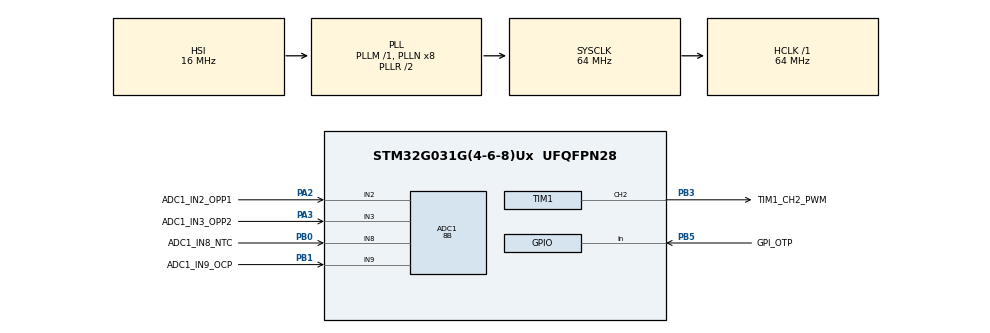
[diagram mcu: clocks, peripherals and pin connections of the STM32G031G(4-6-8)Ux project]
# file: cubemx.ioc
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ADC1.Channel-0\#ChannelRegularConversion=ADC_CHANNEL_2
ADC1.Channel-1\#ChannelRegularConversion=ADC_CHANNEL_3
ADC1.Channel-2\#ChannelRegularConversion=ADC_CHANNEL_8
ADC1.Channel-3\#ChannelRegularConversion=ADC_CHANNEL_9
ADC1.ClockPrescaler=ADC_CLOCK_ASYNC_DIV128
ADC1.ContinuousConvMode=ENABLE
ADC1.DMAContinuousRequests=ENABLE
ADC1.EOCSelection=ADC_EOC_SEQ_CONV
ADC1.ExternalTrigConv=ADC_SOFTWARE_START
ADC1.NbrOfConversion=4
ADC1.NbrOfConversionFlag=1
ADC1.Overrun=ADC_OVR_DATA_OVERWRITTEN
ADC1.Rank-0\#ChannelRegularConversion=1
ADC1.Rank-1\#ChannelRegularConversion=2
ADC1.Rank-2\#ChannelRegularConversion=3
ADC1.Rank-3\#ChannelRegularConversion=4
ADC1.Resolution=ADC_RESOLUTION_8B
ADC1.SamplingTime-0\#ChannelRegularConversion=ADC_SAMPLINGTIME_COMMON_1
ADC1.SamplingTime-1\#ChannelRegularConversion=ADC_SAMPLINGTIME_COMMON_1
ADC1.SamplingTime-2\#ChannelRegularConversion=ADC_SAMPLINGTIME_COMMON_1
ADC1.SamplingTime-3\#ChannelRegularConversion=ADC_SAMPLINGTIME_COMMON_1
ADC1.SamplingTimeCommon1=ADC_SAMPLETIME_19CYCLES_5
ADC1.SamplingTimeCommon2=ADC_SAMPLETIME_19CYCLES_5
ADC1.SelectedChannel=ADC_CHANNEL_2|ADC_CHANNEL_3|ADC_CHANNEL_8|ADC_CHANNEL_9
ADC1.Sequencer=FULLY_CONFIGURABLE
ADC1.master=1
Dma.ADC1.0.Direction=DMA_PERIPH_TO_MEMORY
Dma.ADC1.0.EventEnable=DISABLE
Dma.ADC1.0.Instance=DMA1_Channel1
Dma.ADC1.0.MemDataAlignment=DMA_MDATAALIGN_HALFWORD
Dma.ADC1.0.MemInc=DMA_MINC_ENABLE
Dma.ADC1.0.Mode=DMA_CIRCULAR
Dma.ADC1.0.PeriphDataAlignment=DMA_PDATAALIGN_HALFWORD
Dma.ADC1.0.PeriphInc=DMA_PINC_DISABLE
Dma.ADC1.0.Polarity=HAL_DMAMUX_REQ_GEN_RISING
Dma.ADC1.0.Priority=DMA_PRIORITY_LOW
Dma.ADC1.0.RequestNumber=1
Dma.ADC1.0.SignalID=NONE
Dma.ADC1.0.SyncEnable=DISABLE
Dma.ADC1.0.SyncPolarity=HAL_DMAMUX_SYNC_NO_EVENT
Dma.ADC1.0.SyncRequestNumber=1
Dma.ADC1.0.SyncSignalID=NONE
Dma.Request0=ADC1
Mcu.Family=STM32G0
Mcu.Name=STM32G031G(4-6-8)Ux
Mcu.Package=UFQFPN28
NVIC.DMA1_Channel1_IRQn=true\:3\:0\:true\:false\:true\:false\:true\:true
PA13.Mode=Serial_Wire
PA13.Signal=SYS_SWDIO
PA14-BOOT0.Mode=Serial_Wire
PA14-BOOT0.Signal=SYS_SWCLK
PA2.GPIO_Label=ADC1_IN2_OPP1
PA2.Mode=IN2
PA2.Signal=ADC1_IN2
PA3.GPIO_Label=ADC1_IN3_OPP2
PA3.Mode=IN3
PA3.Signal=ADC1_IN3
PB0.GPIO_Label=ADC1_IN8_NTC
PB0.Mode=IN8
PB0.Signal=ADC1_IN8
PB1.GPIO_Label=ADC1_IN9_OCP
PB1.Mode=IN9
PB1.Signal=ADC1_IN9
PB3.GPIO_Label=TIM1_CH2_PWM
PB3.Signal=S_TIM1_CH2
PB5.GPIO_Label=GPI_OTP
PB5.Signal=GPIO_Input
ProjectManager.HeapSize=0x200
ProjectManager.StackSize=0x400
ProjectManager.TargetToolchain=CMake
RCC.ADCFreq_Value=64000000
RCC.AHBFreq_Value=64000000
RCC.CortexFreq_Value=64000000
RCC.EXTERNAL_CLOCK_VALUE=12288000
RCC.HCLKFreq_Value=64000000
RCC.HSE_VALUE=8000000
RCC.HSI_VALUE=16000000
RCC.LSE_VALUE=32768
RCC.PLLP=RCC_PLLP_DIV8
RCC.PLLQ=RCC_PLLQ_DIV4
RCC.SYSCLKFreq_VALUE=64000000
RCC.SYSCLKSource=RCC_SYSCLKSOURCE_PLLCLK
RCC.VCOOutputFreq_Value=128000000
SH.S_TIM1_CH2.0=TIM1_CH2,PWM Generation2 CH2
TIM1.Break2State=TIM_BREAK2_DISABLE
TIM1.BreakState=TIM_BREAK_DISABLE
TIM1.Channel-PWM\ Generation2\ CH2=TIM_CHANNEL_2
TIM1.OCPolarity_2=TIM_OCPOLARITY_HIGH
TIM1.Prescaler=63
TIM1.TIM_MasterOutputTrigger=TIM_TRGO_RESET
TIM1.TIM_MasterSlaveMode=TIM_MASTERSLAVEMODE_DISABLE
TIM2.Period=1000
TIM2.Prescaler=64-1
VP_TIM1_VS_ClockSourceINT.Mode=Internal
VP_TIM2_VS_ClockSourceINT.Mode=Internal
board=custom

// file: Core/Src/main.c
/* USER CODE BEGIN Header */
/**
  ******************************************************************************
  * @file           : main.c
  * @brief          : Main program body
  ******************************************************************************
  * @attention
  *
  * Copyright (c) 2025 STMicroelectronics.
  * All rights reserved.
  *
  * This software is licensed under terms that can be found in the LICENSE file
  * in the root directory of this software component.
  * If no LICENSE file comes with this software, it is provided AS-IS.
  *
  ******************************************************************************
  */
/* USER CODE END Header */
#include "main.h"
#include "adc.h"
#include "dma.h"
#include "tim.h"
#include "gpio.h"

/* USER CODE BEGIN Includes */
#include "app-framework.h"

/* USER CODE END Includes */

void SystemClock_Config(void);

int main(void)
{

  /* MCU Configuration--------------------------------------------------------*/

  /* Reset of all peripherals, Initializes the Flash interface and the Systick. */
  HAL_Init();

  /* Configure the system clock */
  SystemClock_Config();

  /* Initialize all configured peripherals */
  MX_GPIO_Init();
  MX_DMA_Init();
  MX_ADC1_Init();
  MX_TIM1_Init();
  MX_TIM2_Init();
  /* USER CODE BEGIN 2 */
    AppOnBoot();
    AppOnRun();
  /* USER CODE END 2 */

  /* Infinite loop */
    while (1) {

    }
}

void SystemClock_Config(void)
{
  RCC_OscInitTypeDef RCC_OscInitStruct = {0};
  RCC_ClkInitTypeDef RCC_ClkInitStruct = {0};

  /** Configure the main internal regulator output voltage
  */
  HAL_PWREx_ControlVoltageScaling(PWR_REGULATOR_VOLTAGE_SCALE1);

  /** Initializes the RCC Oscillators according to the specified parameters
  * in the RCC_OscInitTypeDef structure.
  */
  RCC_OscInitStruct.OscillatorType = RCC_OSCILLATORTYPE_HSI;
  RCC_OscInitStruct.HSIState = RCC_HSI_ON;
  RCC_OscInitStruct.HSIDiv = RCC_HSI_DIV1;
  RCC_OscInitStruct.HSICalibrationValue = RCC_HSICALIBRATION_DEFAULT;
  RCC_OscInitStruct.PLL.PLLState = RCC_PLL_ON;
  RCC_OscInitStruct.PLL.PLLSource = RCC_PLLSOURCE_HSI;
  RCC_OscInitStruct.PLL.PLLM = RCC_PLLM_DIV1;
  RCC_OscInitStruct.PLL.PLLN = 8;
  RCC_OscInitStruct.PLL.PLLP = RCC_PLLP_DIV8;
  RCC_OscInitStruct.PLL.PLLQ = RCC_PLLQ_DIV4;
  RCC_OscInitStruct.PLL.PLLR = RCC_PLLR_DIV2;
  if (HAL_RCC_OscConfig(&RCC_OscInitStruct) != HAL_OK)
  {
    Error_Handler();
  }

  /** Initializes the CPU, AHB and APB buses clocks
  */
  RCC_ClkInitStruct.ClockType = RCC_CLOCKTYPE_HCLK|RCC_CLOCKTYPE_SYSCLK
                              |RCC_CLOCKTYPE_PCLK1;
  RCC_ClkInitStruct.SYSCLKSource = RCC_SYSCLKSOURCE_PLLCLK;
  RCC_ClkInitStruct.AHBCLKDivider = RCC_SYSCLK_DIV1;
  RCC_ClkInitStruct.APB1CLKDivider = RCC_HCLK_DIV1;

  if (HAL_RCC_ClockConfig(&RCC_ClkInitStruct, FLASH_LATENCY_2) != HAL_OK)
  {
    Error_Handler();
  }
}

void Error_Handler(void)
{
    __disable_irq();
    while (1) {
    }
}
